VERSION ""

NS_ :

BS_:

BU_: HMI_ECU AEB_ECU ENGINE_ECU
VAL_TABLE_ vtsig_Rador 3 "Zone3 warning" 2 "Zone2 Warning" 1 "Zone1 Warning" 0 "off" ;
VAL_TABLE_ vtsig_Engine 1 "engine is on" 0 "Engine is on" ;

BO_ 272 Break_Message: 1 HMI_ECU
 SG_ Break_Signal : 0|8@1+ (1,0) [0|1] "" Vector__XXX

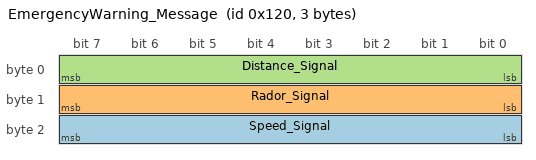
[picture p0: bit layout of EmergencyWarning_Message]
BO_ 288 EmergencyWarning_Message: 3 AEB_ECU
 SG_ Speed_Signal : 16|8@1+ (1,0) [0|120] "" Vector__XXX
 SG_ Rador_Signal : 8|8@1+ (1,0) [0|3] "" Vector__XXX
 SG_ Distance_Signal : 0|8@1+ (1,0) [0|0] "" Vector__XXX

BO_ 304 Acceleration_Message: 1 HMI_ECU
 SG_ Acceleration_Signal : 0|8@1+ (1,0) [0|120] "Km/hr" Vector__XXX

BO_ 320 HMI_Message: 1 AEB_ECU
 SG_ Hmi_Signal : 0|8@1+ (1,0) [0|1] ""  HMI_ECU

BO_ 336 Engine_Message: 1 ENGINE_ECU
 SG_ Engine_Signal : 0|8@1+ (1,0) [0|1] ""  AEB_ECU,HMI_ECU

EV_ Brake_Variable: 0 [0|1] "" 0 1 DUMMY_NODE_VECTOR0 Vector__XXX;

EV_ Zone3_Variable: 0 [0|1] "" 0 2 DUMMY_NODE_VECTOR0 Vector__XXX;

EV_ Zone2_Variable: 0 [0|1] "" 0 3 DUMMY_NODE_VECTOR0 Vector__XXX;

EV_ Zone1_Variable: 0 [0|1] "" 0 4 DUMMY_NODE_VECTOR0 Vector__XXX;

EV_ Rador_Variable: 0 [0|3] "" 0 5 DUMMY_NODE_VECTOR0 Vector__XXX;

EV_ Acce_Variable: 0 [0|288] "" 0 6 DUMMY_NODE_VECTOR0 Vector__XXX;

EV_ Engine_Variable: 0 [0|1] "" 0 7 DUMMY_NODE_VECTOR0 Vector__XXX;

BA_DEF_  "BusType" STRING ;
BA_DEF_DEF_  "BusType" "CAN";
VAL_ 288 Rador_Signal 3 "Zone3 warning" 2 "Zone2 Warning" 1 "Zone1 Warning" 0 "off" ;
VAL_ 336 Engine_Signal 1 "engine is on" 0 "Engine is on" ;
VAL_ Rador_Variable 3 "Zone3 warning" 2 "Zone2 Warning" 1 "Zone1 Warning" 0 "off" ;
VAL_ Engine_Variable 1 "engine is on" 0 "Engine is on" ;
